# LPC802 register map
Vendor: nxp.com; File version: 1.0
CPU: CM0PLUS r0p0, little endian, no MPU, no FPU, VTOR, 2 interrupt priority bits
Registers are 32-bit, read-write, reset 0x0 unless marked. A register's access mark holds for its fields unless they carry their own. Offsets are from the block's base; [hi:lo] are bit positions; {n}, {i} and the like mark numbered series.

## WKT — Wake Up Timer(WKT)
Base 0x40008000
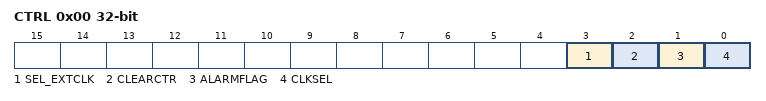
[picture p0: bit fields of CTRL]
0x00 CTRL — Self wake-up timer control register.
  [3] SEL_EXTCLK — Select external or internal clock source for the self wake-up timer. The internal clock source is selected by the CLKSEL bit in this register if SET_EXTCLK is set to internal.
    0=INTERNAL (Internal. The clock source is the internal clock selected by the CLKSEL bit.); 1=EXTERNAL (External. The self wake-up timer uses the external WKTCLKIN pin.)
  [2] CLEARCTR — Clears the self wake-up timer.
    0=NO_EFFECT (No effect. Reading this bit always returns 0.); 1=CLEAR_THE_COUNTER (Clear the counter. Counting is halted until a new count value is loaded.)
  [1] ALARMFLAG — Wake-up or alarm timer flag.
    0=NO_TIME_OUT (No time-out. The self wake-up timer has not timed out. Writing a 0 to has no effect.); 1=TIME_OUT (Time-out. The self wake-up timer has timed out. This flag generates an interrupt request which can wake up the part from any reduced power mode including Deep power-down if the clock source is the low power oscillator. Writing a 1 clears this status bit.)
  [0] CLKSEL — Select the self wake-up timer clock source. Remark: This bit only has an effect if the SEL_EXTCLK bit is not set.
    0=DIVIDED_IRC_CLOCK (Divided IRC clock. This clock runs at 750 kHz and provides time-out periods of up to approximately 95 minutes in 1.33 us increments. Remark: This clock is not available in not available in Deep-sleep, power-down, deep power-down modes. Do not select this option if the timer is to be used to wake up from one of these modes.); 1=LOW_POWER_CLOCK (This is the (nominally) 10 kHz clock and provides time-out periods of up to approximately 119 hours in 100 us increments. The accuracy of this clock is limited to +/- 40 % over temperature and processing. Remark: This clock is available in all power modes. Prior to use, the low-power oscillator must be enabled. The oscillator must also be set to remain active in Deep power-down if needed.)
0x0C COUNT reset not defined — Counter register.
  [31:0] VALUE — A write to this register pre-loads start count value into the timer and starts the count-down sequence. A read reflects the current value of the timer.

## PMU
Base 0x40020000
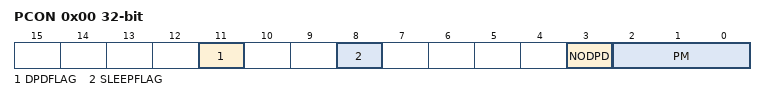
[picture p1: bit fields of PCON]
0x00 PCON — Power control register
  [11] DPDFLAG — Deep power-down flag
    0=NOT_DEEP_POWER_DOWN (Not Deep power-down. Read: Deep power-down mode not entered. Write: No effect.); 1=DEEP_POWER_DOWN (Deep power-down. Read: Deep power-down mode entered. Write: Clear the Deep power-down flag.)
  [8] SLEEPFLAG — Sleep mode flag
    0=ACTIVE_MODE (Active mode. Read: No power-down mode entered. Part is in Active mode. Write: No effect.); 1=LOW_POWER_MODE (Low power mode. Read: Sleep, Deep-sleep or Power-down mode entered. Write: Writing a 1 clears the SLEEPFLAG bit to 0.)
  [3] NODPD — A 1 in this bit prevents entry to Deep power-down mode when 0x3 is written to the PM field above, the SLEEPDEEP bit is set, and a WFI is executed. This bit is cleared only by power-on reset, so writing a one to this bit locks the part in a mode in which Deep power-down mode is blocked.
  [2:0] PM — Power mode
    0=DEFAULT (Default. The part is in active or sleep mode.); 1=DEEP_SLEEP_MODE (Deep-sleep mode. ARM WFI will enter Deep-sleep mode.); 2=POWER_DOWN_MODE (Power-down mode. ARM WFI will enter Power-down mode.); 3=DEEP_POWER_DOWN_MODE (Deep power-down mode. ARM WFI will enter Deep-power down mode (ARM Cortex-M0+ core powered-down).)
{0x4+4i} GPREG[{i}] (i=0..4) — General purpose register N
  [31:0] GPDATA — Data retained during Deep power-down mode.
0x20 WUSRCREG — Pin wake-up source register
  [7:0] WUSRCREG — Pin wake-up source
0x24 WUENAREG — Pin wake-up enable register
  [7:0] WUENAREG — Pin wake-up enable
